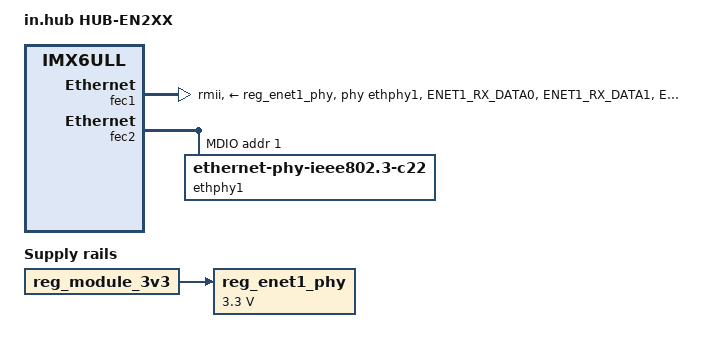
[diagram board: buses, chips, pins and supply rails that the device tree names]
// SPDX-License-Identifier: GPL-2.0-only
/*
 * Copyright 2026 in.hub GmbH
 */

/dts-v1/;

#include "imx6ull-inhub-hub-en200.dts"

/ {
	model = "in.hub HUB-EN2XX";
	compatible = "inhub,hub-en2xx", "fsl,imx6ull";

	reg_enet1_phy: regulator-enet1-phy {
		compatible = "regulator-fixed-clock";
		regulator-boot-on;
		regulator-min-microvolt = <3300000>;
		regulator-max-microvolt = <3300000>;
		regulator-name = "+V3.3_ENET1";
		vin-supply = <&reg_module_3v3>;
		clocks = <&clks IMX6UL_CLK_ENET1_REF_125M>;
		startup-delay-us = <150000>;
	};
};

&iomuxc {
	pinctrl_enet1: enet1grp {
		fsl,pins = <
			MX6UL_PAD_ENET1_RX_DATA0__ENET1_RDATA00	0x1b0b0
			MX6UL_PAD_ENET1_RX_DATA1__ENET1_RDATA01	0x1b0b0
			MX6UL_PAD_ENET1_RX_EN__ENET1_RX_EN		0x1b0b0
			MX6UL_PAD_ENET1_RX_ER__ENET1_RX_ER  	0x1b0b0
			MX6UL_PAD_ENET1_TX_DATA0__ENET1_TDATA00	0x1b0b0
			MX6UL_PAD_ENET1_TX_DATA1__ENET1_TDATA01	0x1b0b0
			MX6UL_PAD_ENET1_TX_EN__ENET1_TX_EN		0x1b0b0
			MX6UL_PAD_ENET1_TX_CLK__ENET1_REF_CLK1	0x4001b031
		>;
	};
};

&fec1 {
	pinctrl-names = "default";
	pinctrl-0 = <&pinctrl_enet1>;
	phy-mode = "rmii";
	phy-handle = <&ethphy1>;
	phy-supply = <&reg_enet1_phy>;
	status = "okay";
};

&fec2 {
	mdio {
		ethphy1: ethernet-phy@1 {
			compatible = "ethernet-phy-ieee802.3-c22";
			max-speed = <100>;
			reg = <1>;
			assigned-clocks = <&clks IMX6UL_CLK_ENET_REF>;
			assigned-clock-rates = <50000000>;
		};
	};
};
